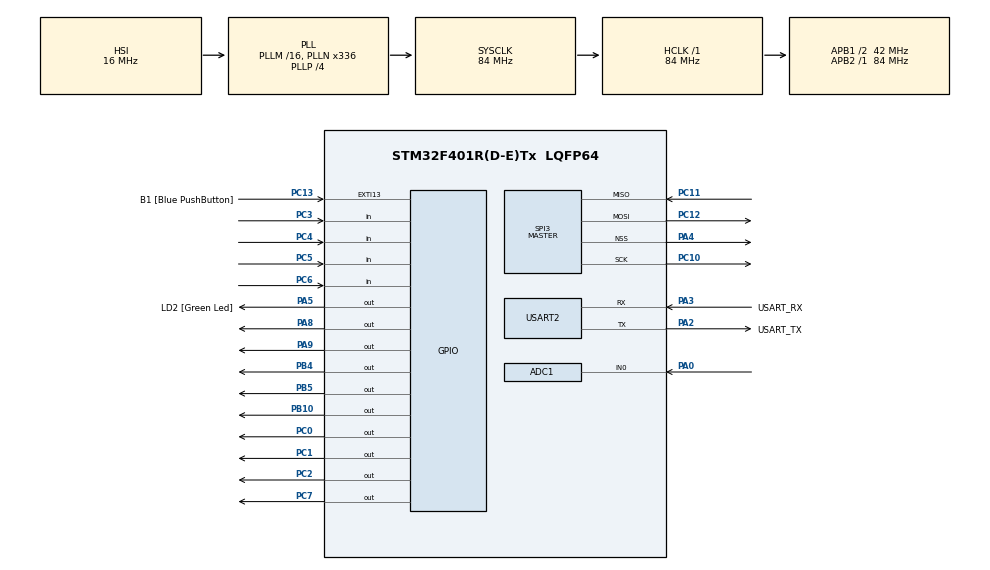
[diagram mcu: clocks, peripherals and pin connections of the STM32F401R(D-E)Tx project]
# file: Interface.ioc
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ADC1.Channel-0\#ChannelRegularConversion=ADC_CHANNEL_0
ADC1.NbrOfConversionFlag=1
ADC1.Rank-0\#ChannelRegularConversion=1
ADC1.SamplingTime-0\#ChannelRegularConversion=ADC_SAMPLETIME_3CYCLES
ADC1.master=1
Mcu.Family=STM32F4
Mcu.Name=STM32F401R(D-E)Tx
Mcu.Package=LQFP64
NVIC.PriorityGroup=NVIC_PRIORITYGROUP_0
PA0-WKUP.Signal=ADCx_IN0
PA13.GPIO_Label=TMS
PA13.Mode=Serial_Wire
PA13.Signal=SYS_JTMS-SWDIO
PA14.GPIO_Label=TCK
PA14.Mode=Serial_Wire
PA14.Signal=SYS_JTCK-SWCLK
PA2.GPIO_Label=USART_TX
PA2.GPIO_Mode=GPIO_MODE_AF_PP
PA2.GPIO_PuPd=GPIO_NOPULL
PA2.GPIO_Speed=GPIO_SPEED_FREQ_LOW
PA2.Mode=Asynchronous
PA2.Signal=USART2_TX
PA3.GPIO_Label=USART_RX
PA3.GPIO_Mode=GPIO_MODE_AF_PP
PA3.GPIO_PuPd=GPIO_NOPULL
PA3.GPIO_Speed=GPIO_SPEED_FREQ_LOW
PA3.Mode=Asynchronous
PA3.Signal=USART2_RX
PA4.Mode=NSS_Signal_Hard_Output
PA4.Signal=SPI3_NSS
PA5.GPIO_Label=LD2 [Green Led]
PA5.GPIO_Mode=GPIO_MODE_OUTPUT_PP
PA5.GPIO_PuPd=GPIO_NOPULL
PA5.GPIO_Speed=GPIO_SPEED_FREQ_LOW
PA5.Signal=GPIO_Output
PA8.Signal=GPIO_Output
PA9.Signal=GPIO_Output
PB10.Signal=GPIO_Output
PB4.Signal=GPIO_Output
PB5.Signal=GPIO_Output
PC0.Signal=GPIO_Output
PC1.Signal=GPIO_Output
PC10.Mode=Full_Duplex_Master
PC10.Signal=SPI3_SCK
PC11.Mode=Full_Duplex_Master
PC11.Signal=SPI3_MISO
PC12.Mode=Full_Duplex_Master
PC12.Signal=SPI3_MOSI
PC13-ANTI_TAMP.GPIO_Label=B1 [Blue PushButton]
PC13-ANTI_TAMP.GPIO_ModeDefaultEXTI=GPIO_MODE_IT_FALLING
PC13-ANTI_TAMP.GPIO_PuPd=GPIO_NOPULL
PC13-ANTI_TAMP.Signal=GPXTI13
PC14-OSC32_IN.Mode=LSE-External-Oscillator
PC14-OSC32_IN.Signal=RCC_OSC32_IN
PC15-OSC32_OUT.Mode=LSE-External-Oscillator
PC15-OSC32_OUT.Signal=RCC_OSC32_OUT
PC2.Signal=GPIO_Output
PC3.Signal=GPIO_Input
PC4.Signal=GPIO_Input
PC5.Signal=GPIO_Input
PC6.Signal=GPIO_Input
PC7.Signal=GPIO_Output
PH0\ -\ OSC_IN.Mode=HSE-External-Clock-Source
PH0\ -\ OSC_IN.Signal=RCC_OSC_IN
PH1\ -\ OSC_OUT.Mode=HSE-External-Clock-Source
PH1\ -\ OSC_OUT.Signal=RCC_OSC_OUT
ProjectManager.HeapSize=0x200
ProjectManager.StackSize=0x400
ProjectManager.TargetToolchain=MDK-ARM V5.32
RCC.48MHZClocksFreq_Value=48000000
RCC.AHBFreq_Value=84000000
RCC.APB1CLKDivider=RCC_HCLK_DIV2
RCC.APB1Freq_Value=42000000
RCC.APB1TimFreq_Value=84000000
RCC.APB2Freq_Value=84000000
RCC.APB2TimFreq_Value=84000000
RCC.CortexFreq_Value=84000000
RCC.HCLKFreq_Value=84000000
RCC.HSE_VALUE=8000000
RCC.HSI_VALUE=16000000
RCC.PLLN=336
RCC.PLLP=RCC_PLLP_DIV4
RCC.PLLQ=7
RCC.SYSCLKFreq_VALUE=84000000
RCC.SYSCLKSource=RCC_SYSCLKSOURCE_PLLCLK
RCC.VCOOutputFreq_Value=336000000
SH.ADCx_IN0.0=ADC1_IN0,IN0
SPI3.Direction=SPI_DIRECTION_2LINES
SPI3.Mode=SPI_MODE_MASTER
SPI3.VirtualType=VM_MASTER
USART2.VirtualMode=VM_ASYNC
VP_TIM3_VS_ClockSourceINT.Mode=Internal
board=NUCLEO-F401RE

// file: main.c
/* USER CODE BEGIN Header */
/**
  ******************************************************************************
  * @file           : main.c
  * @brief          : Main program body
  ******************************************************************************
  * @attention
  *
  * Copyright (c) 2023 STMicroelectronics.
  * All rights reserved.
  *
  * This software is licensed under terms that can be found in the LICENSE file
  * in the root directory of this software component.
  * If no LICENSE file comes with this software, it is provided AS-IS.
  *
  ******************************************************************************
  */
/* USER CODE END Header */
#include <stdio.h>
#include <stdlib.h>
#include "main.h"
#include "adc.h"
#include "spi.h"
#include "tim.h"
#include "usart.h"
#include "gpio.h"
#include "LCD.h"

void SystemClock_Config(void);
/* USER CODE BEGIN PFP */
int get_keypad_number(int keypad_num);
int keypad_output(int column, int in1, int in2, int in3, int in4);
int enter_keypad(char str[32], int gradient, int intercept);

/* USER CODE END PFP */

int main(void)
{

  /* MCU Configuration--------------------------------------------------------*/

  /* Reset of all peripherals, Initializes the Flash interface and the Systick. */
  HAL_Init();

  /* Configure the system clock */
  SystemClock_Config();

  /* Initialize all configured peripherals */
  MX_GPIO_Init();
  MX_ADC1_Init();
  MX_SPI3_Init();
  MX_USART2_UART_Init();
  MX_TIM3_Init();
  /* USER CODE BEGIN 2 */
	LCD_Puts(11, 0, "99243009");
	LCD_Puts(11, 1, "99243076");
	HAL_Delay(200);
	LCD_Clear();

	uint16_t keypad_num = 20;
	uint8_t recieve = 0;

	char str[32];
  /* USER CODE END 2 */

  /* Infinite loop */
  while (1)
  {
		LCD_Puts(0, 10, "Choose your wave:");
		HAL_Delay(200);
		LCD_Clear();
		LCD_Puts(2, 0, "1:Sine  2:Square 3:Triangle");
		LCD_Puts(2, 1, "4:AbsSine 5:Step 6:Sawtooth");
		HAL_Delay(200);
		keypad_num = get_keypad_number(keypad_num);
		LCD_Clear();
		sprintf(str, "%d", keypad_num);
		LCD_Puts(0, 5, str);
		HAL_Delay(200);
		LCD_Clear();

		LCD_Puts(0, 0, "Set the Durration:");
		//HAL_Delay(500);
		uint16_t duration = enter_keypad(str, 9500, 500);
		LCD_Clear();
		//sprintf(str, "%d", duration);
		//LCD_Puts(0, 0, str);
		//HAL_Delay(200);
		//LCD_Clear();
		LCD_Puts(0, 0, "Set the Frequency:");
		uint16_t frequency = enter_keypad(str, 999, 1);

		LCD_Clear();

		//LCD_Puts(0, 0, str);
		//HAL_Delay(500);
		switch (keypad_num){
			case 1:
				LCD_Puts(10, 0, "Sine");
				break;
			case 2:
				LCD_Puts(10, 0, "Square");
				break;
			case 3:
				LCD_Puts(10, 0, "Triangle");
				break;
			case 4:
				LCD_Puts(10, 0, "AbsSine");
				break;
			case 5:
				LCD_Puts(10, 0, "Step");
				break;
			case 6:
				LCD_Puts(10, 0, "Sawtooth");
				break;
			default:
				LCD_Puts(9, 0, "Invalid Number!");
				break;
		}
		HAL_GPIO_WritePin(GPIOA,GPIO_PIN_4,GPIO_PIN_RESET);
		uint8_t *packet = (uint8_t*) malloc(3* sizeof(uint8_t));
		//uint16_t packet[3] = {keypad_num, duration, frequency};
		packet[0] = (uint8_t)keypad_num;
		packet[1] = (uint8_t)keypad_num >> 8;
		packet[2] = (uint8_t)duration;
		packet[3] = (uint8_t)duration >> 8;
		packet[4] = (uint8_t)frequency;
		packet[5] = (uint8_t)frequency >> 8;
		HAL_SPI_Transmit(&hspi3, packet, 6, HAL_MAX_DELAY);
		//HAL_SPI_Receive(&hspi3, &recieve, 1, HAL_MAX_DELAY);
		HAL_Delay(500);
		LCD_Clear();
		//sprintf(str, "%d", recieve);
		//LCD_Puts(0,0, str);
		//HAL_Delay(1000);
		//if (recieve == 0)
			//LCD_Puts(0, 0, "Operation successful!");
		//HAL_SPI_Receive();
		//HAL_Delay(200);
		LCD_Clear();
		keypad_num = 20;
  }
}

int enter_keypad(char str[32], int gradient, int intercept){
	float Voltage = 0;
	int keypad_num;
	do {

		HAL_GPIO_WritePin(GPIOC, GPIO_PIN_0, GPIO_PIN_SET);
		HAL_GPIO_WritePin(GPIOC, GPIO_PIN_1, GPIO_PIN_SET);
		HAL_GPIO_WritePin(GPIOC, GPIO_PIN_2, GPIO_PIN_RESET);

		keypad_num = keypad_output(3, HAL_GPIO_ReadPin(GPIOC, GPIO_PIN_3), HAL_GPIO_ReadPin(GPIOC, GPIO_PIN_4), HAL_GPIO_ReadPin(GPIOC, GPIO_PIN_5), HAL_GPIO_ReadPin(GPIOC, GPIO_PIN_6));

		uint32_t ADC_Value;
		HAL_ADC_Start(&hadc1);
		HAL_ADC_PollForConversion(&hadc1, HAL_MAX_DELAY);
		ADC_Value = HAL_ADC_GetValue(&hadc1);
		if (Voltage != (float)(ADC_Value) / (4095)){
			Voltage = (float)(ADC_Value) / (4095);
			float temp = Voltage * gradient + intercept;
			if (temp < 10000 && temp >= 1000)
				sprintf(str, "0%d", (int)temp);
			else if (temp < 1000 && temp >= 100)
				sprintf(str, "00%d", (int)temp);
			else if (temp < 100 && temp >= 10)
				sprintf(str, "000%d", (int)temp);
			else if (temp < 10 && temp >= 1)
				sprintf(str, "0000%d", (int)temp);
			else
				sprintf(str, "%d", (int)temp);

			LCD_Puts(0, 1, str);
		}

	}
	while(keypad_num != -1);
	return Voltage * gradient + intercept;
}

int get_keypad_number(int keypad_num)
{
	do {

		HAL_GPIO_WritePin(GPIOC, GPIO_PIN_0, GPIO_PIN_RESET);
		HAL_GPIO_WritePin(GPIOC, GPIO_PIN_1, GPIO_PIN_SET);
		HAL_GPIO_WritePin(GPIOC, GPIO_PIN_2, GPIO_PIN_SET);

		keypad_num = keypad_output(1, HAL_GPIO_ReadPin(GPIOC, GPIO_PIN_3), HAL_GPIO_ReadPin(GPIOC, GPIO_PIN_4), HAL_GPIO_ReadPin(GPIOC, GPIO_PIN_5), HAL_GPIO_ReadPin(GPIOC, GPIO_PIN_6));

		if (keypad_num != 20)
			return keypad_num;

		HAL_GPIO_WritePin(GPIOC, GPIO_PIN_0, GPIO_PIN_SET);
		HAL_GPIO_WritePin(GPIOC, GPIO_PIN_1, GPIO_PIN_RESET);
		HAL_GPIO_WritePin(GPIOC, GPIO_PIN_2, GPIO_PIN_SET);

		keypad_num = keypad_output(2, HAL_GPIO_ReadPin(GPIOC, GPIO_PIN_3), HAL_GPIO_ReadPin(GPIOC, GPIO_PIN_4), HAL_GPIO_ReadPin(GPIOC, GPIO_PIN_5), HAL_GPIO_ReadPin(GPIOC, GPIO_PIN_6));

		if (keypad_num != 20)
			return keypad_num;

		HAL_GPIO_WritePin(GPIOC, GPIO_PIN_0, GPIO_PIN_SET);
		HAL_GPIO_WritePin(GPIOC, GPIO_PIN_1, GPIO_PIN_SET);
		HAL_GPIO_WritePin(GPIOC, GPIO_PIN_2, GPIO_PIN_RESET);

		keypad_num = keypad_output(3, HAL_GPIO_ReadPin(GPIOC, GPIO_PIN_3), HAL_GPIO_ReadPin(GPIOC, GPIO_PIN_4), HAL_GPIO_ReadPin(GPIOC, GPIO_PIN_5), HAL_GPIO_ReadPin(GPIOC, GPIO_PIN_6));
	}
	while(keypad_num == 20);
	return keypad_num;
}

int keypad_output(int column, int in1, int in2, int in3, int in4){
	if (in1 == 0)
		return column + 0;
	if (in2 == 0)
		return column + 3;
	if (in3 == 0)
		return column + 6;
	if (in4 == 0 && column == 2)
		return 0;
	if (in4 == 0 && column == 3)
		return -1;
	return 20;
}

void SystemClock_Config(void)
{
  RCC_OscInitTypeDef RCC_OscInitStruct = {0};
  RCC_ClkInitTypeDef RCC_ClkInitStruct = {0};

  /** Configure the main internal regulator output voltage
  */
  __HAL_RCC_PWR_CLK_ENABLE();
  __HAL_PWR_VOLTAGESCALING_CONFIG(PWR_REGULATOR_VOLTAGE_SCALE2);

  /** Initializes the RCC Oscillators according to the specified parameters
  * in the RCC_OscInitTypeDef structure.
  */
  RCC_OscInitStruct.OscillatorType = RCC_OSCILLATORTYPE_HSI;
  RCC_OscInitStruct.HSIState = RCC_HSI_ON;
  RCC_OscInitStruct.HSICalibrationValue = RCC_HSICALIBRATION_DEFAULT;
  RCC_OscInitStruct.PLL.PLLState = RCC_PLL_ON;
  RCC_OscInitStruct.PLL.PLLSource = RCC_PLLSOURCE_HSI;
  RCC_OscInitStruct.PLL.PLLM = 16;
  RCC_OscInitStruct.PLL.PLLN = 336;
  RCC_OscInitStruct.PLL.PLLP = RCC_PLLP_DIV4;
  RCC_OscInitStruct.PLL.PLLQ = 7;
  if (HAL_RCC_OscConfig(&RCC_OscInitStruct) != HAL_OK)
  {
    Error_Handler();
  }

  /** Initializes the CPU, AHB and APB buses clocks
  */
  RCC_ClkInitStruct.ClockType = RCC_CLOCKTYPE_HCLK|RCC_CLOCKTYPE_SYSCLK
                              |RCC_CLOCKTYPE_PCLK1|RCC_CLOCKTYPE_PCLK2;
  RCC_ClkInitStruct.SYSCLKSource = RCC_SYSCLKSOURCE_PLLCLK;
  RCC_ClkInitStruct.AHBCLKDivider = RCC_SYSCLK_DIV1;
  RCC_ClkInitStruct.APB1CLKDivider = RCC_HCLK_DIV2;
  RCC_ClkInitStruct.APB2CLKDivider = RCC_HCLK_DIV1;

  if (HAL_RCC_ClockConfig(&RCC_ClkInitStruct, FLASH_LATENCY_2) != HAL_OK)
  {
    Error_Handler();
  }
}

void Error_Handler(void)
{
  __disable_irq();
  while (1)
  {
  }
}
